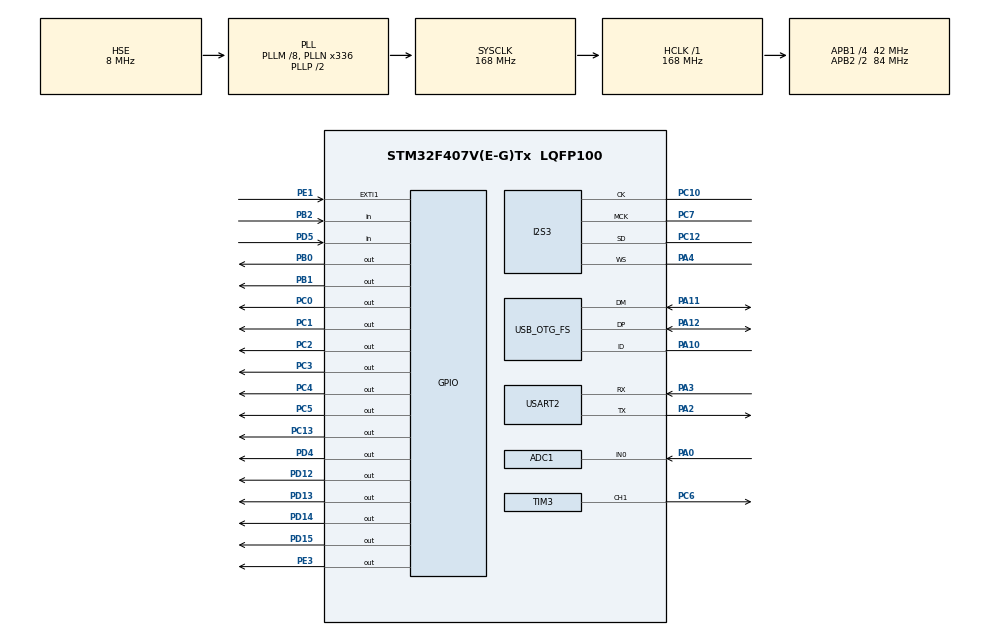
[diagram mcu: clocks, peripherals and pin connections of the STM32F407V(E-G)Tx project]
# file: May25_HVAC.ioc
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ADC1.Channel-0\#ChannelRegularConversion=ADC_CHANNEL_0
ADC1.NbrOfConversionFlag=1
ADC1.Rank-0\#ChannelRegularConversion=1
ADC1.SamplingTime-0\#ChannelRegularConversion=ADC_SAMPLETIME_3CYCLES
ADC1.master=1
I2S3.AudioFreq=I2S_AUDIOFREQ_48K
I2S3.ErrorAudioFreq=-2.34 %
I2S3.FullDuplexMode=I2S_FULLDUPLEXMODE_DISABLE
I2S3.Instance=SPI$Index
I2S3.RealAudioFreq=46.875 KHz
I2S3.VirtualMode=I2S_MODE_MASTER
Mcu.Family=STM32F4
Mcu.Name=STM32F407V(E-G)Tx
Mcu.Package=LQFP100
NVIC.PriorityGroup=NVIC_PRIORITYGROUP_4
PA0-WKUP.Signal=ADCx_IN0
PA10.Mode=OTG/Dual_Role_Device
PA10.Signal=USB_OTG_FS_ID
PA11.Mode=OTG/Dual_Role_Device
PA11.Signal=USB_OTG_FS_DM
PA12.Mode=OTG/Dual_Role_Device
PA12.Signal=USB_OTG_FS_DP
PA13.Signal=SYS_JTMS-SWDIO
PA14.Signal=SYS_JTCK-SWCLK
PA2.Mode=Asynchronous
PA2.Signal=USART2_TX
PA3.Mode=Asynchronous
PA3.Signal=USART2_RX
PA4.Mode=Half_Duplex_Master
PA4.Signal=I2S3_WS
PA9.Signal=USB_OTG_FS_VBUS
PB0.Signal=GPIO_Output
PB1.Signal=GPIO_Output
PB10.Signal=I2S2_CK
PB2.Signal=GPIO_Input
PB3.Signal=SYS_JTDO-SWO
PC0.Signal=GPIO_Output
PC1.Signal=GPIO_Output
PC10.Mode=Half_Duplex_Master
PC10.Signal=I2S3_CK
PC12.Mode=Half_Duplex_Master
PC12.Signal=I2S3_SD
PC13-ANTI_TAMP.Signal=GPIO_Output
PC14-OSC32_IN.Mode=LSE-External-Oscillator
PC14-OSC32_IN.Signal=RCC_OSC32_IN
PC15-OSC32_OUT.Mode=LSE-External-Oscillator
PC15-OSC32_OUT.Signal=RCC_OSC32_OUT
PC2.Signal=GPIO_Output
PC3.Signal=GPIO_Output
PC4.Signal=GPIO_Output
PC5.Signal=GPIO_Output
PC6.Signal=S_TIM3_CH1
PC7.Mode=Master_Clock_Activated
PC7.Signal=I2S3_MCK
PD12.Signal=GPIO_Output
PD13.Signal=GPIO_Output
PD14.Signal=GPIO_Output
PD15.Signal=GPIO_Output
PD4.Signal=GPIO_Output
PD5.Signal=GPIO_Input
PE1.Signal=GPXTI1
PE3.Signal=GPIO_Output
PH0-OSC_IN.Mode=HSE-External-Oscillator
PH0-OSC_IN.Signal=RCC_OSC_IN
PH1-OSC_OUT.Mode=HSE-External-Oscillator
PH1-OSC_OUT.Signal=RCC_OSC_OUT
ProjectManager.HeapSize=0x200
ProjectManager.StackSize=0x400
ProjectManager.TargetToolchain=STM32CubeIDE
RCC.48MHZClocksFreq_Value=48000000
RCC.AHBFreq_Value=168000000
RCC.APB1CLKDivider=RCC_HCLK_DIV4
RCC.APB1Freq_Value=42000000
RCC.APB1TimFreq_Value=84000000
RCC.APB2CLKDivider=RCC_HCLK_DIV2
RCC.APB2Freq_Value=84000000
RCC.APB2TimFreq_Value=168000000
RCC.CortexFreq_Value=168000000
RCC.HCLKFreq_Value=168000000
RCC.HSE_VALUE=8000000
RCC.HSI_VALUE=16000000
RCC.PLLM=8
RCC.PLLN=336
RCC.PLLQ=7
RCC.SYSCLKFreq_VALUE=168000000
RCC.SYSCLKSource=RCC_SYSCLKSOURCE_PLLCLK
RCC.VCOOutputFreq_Value=336000000
SH.ADCx_IN0.0=ADC1_IN0,IN0
SH.S_TIM3_CH1.0=TIM3_CH1,PWM Generation1 CH1
TIM3.Channel-PWM\ Generation1\ CH1=TIM_CHANNEL_1
TIM3.Period=999
TIM3.Prescaler=83
TIM3.Pulse-PWM\ Generation1\ CH1=800
USART2.VirtualMode=VM_ASYNC
board=custom

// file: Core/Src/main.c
/* USER CODE BEGIN Header */
/**
  ******************************************************************************
  * @file           : main.c
  * @brief          : Main program body
  ******************************************************************************
  * @attention
  *
  * Copyright (c) 2026 STMicroelectronics.
  * All rights reserved.
  *
  * This software is licensed under terms that can be found in the LICENSE file
  * in the root directory of this software component.
  * If no LICENSE file comes with this software, it is provided AS-IS.
  *
  ******************************************************************************
  */
/* USER CODE END Header */
#include "main.h"

/* USER CODE BEGIN Includes */
#include "hvac_app.h"
/* USER CODE END Includes */

ADC_HandleTypeDef hadc1;

I2S_HandleTypeDef hi2s3;

TIM_HandleTypeDef htim3;

UART_HandleTypeDef huart2;

void SystemClock_Config(void);
static void MX_GPIO_Init(void);
static void MX_ADC1_Init(void);
static void MX_TIM3_Init(void);
static void MX_USART2_UART_Init(void);
static void MX_I2S3_Init(void);
static void MX_USB_OTG_FS_USB_Init(void);

int main(void)
{

  /* MCU Configuration--------------------------------------------------------*/

  /* Reset of all peripherals, Initializes the Flash interface and the Systick. */
  HAL_Init();

  /* Configure the system clock */
  SystemClock_Config();

  /* Initialize all configured peripherals */
  MX_GPIO_Init();
  MX_ADC1_Init();
  MX_TIM3_Init();
  MX_USART2_UART_Init();
  MX_I2S3_Init();
  MX_USB_OTG_FS_USB_Init();
  /* USER CODE BEGIN 2 */
  hvac_app_init();
  /* USER CODE END 2 */

  /* Infinite loop */
  while (1)
  {

    /* USER CODE BEGIN 3 */
    hvac_app_task();
  }
  /* USER CODE END 3 */
}

void SystemClock_Config(void)
{
  RCC_OscInitTypeDef RCC_OscInitStruct = {0};
  RCC_ClkInitTypeDef RCC_ClkInitStruct = {0};

  /** Configure the main internal regulator output voltage
  */
  __HAL_RCC_PWR_CLK_ENABLE();
  __HAL_PWR_VOLTAGESCALING_CONFIG(PWR_REGULATOR_VOLTAGE_SCALE1);

  /** Initializes the RCC Oscillators according to the specified parameters
  * in the RCC_OscInitTypeDef structure.
  */
  RCC_OscInitStruct.OscillatorType = RCC_OSCILLATORTYPE_HSE;
  RCC_OscInitStruct.HSEState = RCC_HSE_ON;
  RCC_OscInitStruct.PLL.PLLState = RCC_PLL_ON;
  RCC_OscInitStruct.PLL.PLLSource = RCC_PLLSOURCE_HSE;
  RCC_OscInitStruct.PLL.PLLM = 8;
  RCC_OscInitStruct.PLL.PLLN = 336;
  RCC_OscInitStruct.PLL.PLLP = RCC_PLLP_DIV2;
  RCC_OscInitStruct.PLL.PLLQ = 7;
  if (HAL_RCC_OscConfig(&RCC_OscInitStruct) != HAL_OK)
  {
    Error_Handler();
  }

  /** Initializes the CPU, AHB and APB buses clocks
  */
  RCC_ClkInitStruct.ClockType = RCC_CLOCKTYPE_HCLK|RCC_CLOCKTYPE_SYSCLK
                              |RCC_CLOCKTYPE_PCLK1|RCC_CLOCKTYPE_PCLK2;
  RCC_ClkInitStruct.SYSCLKSource = RCC_SYSCLKSOURCE_PLLCLK;
  RCC_ClkInitStruct.AHBCLKDivider = RCC_SYSCLK_DIV1;
  RCC_ClkInitStruct.APB1CLKDivider = RCC_HCLK_DIV4;
  RCC_ClkInitStruct.APB2CLKDivider = RCC_HCLK_DIV2;

  if (HAL_RCC_ClockConfig(&RCC_ClkInitStruct, FLASH_LATENCY_5) != HAL_OK)
  {
    Error_Handler();
  }
}

static void MX_ADC1_Init(void)
{

  ADC_ChannelConfTypeDef sConfig = {0};

  /** Configure the global features of the ADC (Clock, Resolution, Data Alignment and number of conversion)
  */
  hadc1.Instance = ADC1;
  hadc1.Init.ClockPrescaler = ADC_CLOCK_SYNC_PCLK_DIV4;
  hadc1.Init.Resolution = ADC_RESOLUTION_12B;
  hadc1.Init.ScanConvMode = DISABLE;
  hadc1.Init.ContinuousConvMode = DISABLE;
  hadc1.Init.DiscontinuousConvMode = DISABLE;
  hadc1.Init.ExternalTrigConvEdge = ADC_EXTERNALTRIGCONVEDGE_NONE;
  hadc1.Init.ExternalTrigConv = ADC_SOFTWARE_START;
  hadc1.Init.DataAlign = ADC_DATAALIGN_RIGHT;
  hadc1.Init.NbrOfConversion = 1;
  hadc1.Init.DMAContinuousRequests = DISABLE;
  hadc1.Init.EOCSelection = ADC_EOC_SINGLE_CONV;
  if (HAL_ADC_Init(&hadc1) != HAL_OK)
  {
    Error_Handler();
  }

  /** Configure for the selected ADC regular channel its corresponding rank in the sequencer and its sample time.
  */
  sConfig.Channel = ADC_CHANNEL_0;
  sConfig.Rank = 1;
  sConfig.SamplingTime = ADC_SAMPLETIME_3CYCLES;
  if (HAL_ADC_ConfigChannel(&hadc1, &sConfig) != HAL_OK)
  {
    Error_Handler();
  }

}

static void MX_I2S3_Init(void)
{

  hi2s3.Instance = SPI3;
  hi2s3.Init.Mode = I2S_MODE_MASTER_TX;
  hi2s3.Init.Standard = I2S_STANDARD_PHILIPS;
  hi2s3.Init.DataFormat = I2S_DATAFORMAT_16B;
  hi2s3.Init.MCLKOutput = I2S_MCLKOUTPUT_ENABLE;
  hi2s3.Init.AudioFreq = I2S_AUDIOFREQ_48K;
  hi2s3.Init.CPOL = I2S_CPOL_LOW;
  hi2s3.Init.ClockSource = I2S_CLOCK_PLL;
  hi2s3.Init.FullDuplexMode = I2S_FULLDUPLEXMODE_DISABLE;
  if (HAL_I2S_Init(&hi2s3) != HAL_OK)
  {
    Error_Handler();
  }

}

static void MX_TIM3_Init(void)
{

  TIM_MasterConfigTypeDef sMasterConfig = {0};
  TIM_OC_InitTypeDef sConfigOC = {0};

  htim3.Instance = TIM3;
  htim3.Init.Prescaler = 83;
  htim3.Init.CounterMode = TIM_COUNTERMODE_UP;
  htim3.Init.Period = 999;
  htim3.Init.ClockDivision = TIM_CLOCKDIVISION_DIV1;
  htim3.Init.AutoReloadPreload = TIM_AUTORELOAD_PRELOAD_DISABLE;
  if (HAL_TIM_PWM_Init(&htim3) != HAL_OK)
  {
    Error_Handler();
  }
  sMasterConfig.MasterOutputTrigger = TIM_TRGO_RESET;
  sMasterConfig.MasterSlaveMode = TIM_MASTERSLAVEMODE_DISABLE;
  if (HAL_TIMEx_MasterConfigSynchronization(&htim3, &sMasterConfig) != HAL_OK)
  {
    Error_Handler();
  }
  sConfigOC.OCMode = TIM_OCMODE_PWM1;
  sConfigOC.Pulse = 800;
  sConfigOC.OCPolarity = TIM_OCPOLARITY_HIGH;
  sConfigOC.OCFastMode = TIM_OCFAST_DISABLE;
  if (HAL_TIM_PWM_ConfigChannel(&htim3, &sConfigOC, TIM_CHANNEL_1) != HAL_OK)
  {
    Error_Handler();
  }
  HAL_TIM_MspPostInit(&htim3);

}

static void MX_USART2_UART_Init(void)
{

  huart2.Instance = USART2;
  huart2.Init.BaudRate = 115200;
  huart2.Init.WordLength = UART_WORDLENGTH_8B;
  huart2.Init.StopBits = UART_STOPBITS_1;
  huart2.Init.Parity = UART_PARITY_NONE;
  huart2.Init.Mode = UART_MODE_TX_RX;
  huart2.Init.HwFlowCtl = UART_HWCONTROL_NONE;
  huart2.Init.OverSampling = UART_OVERSAMPLING_16;
  if (HAL_UART_Init(&huart2) != HAL_OK)
  {
    Error_Handler();
  }

}

static void MX_USB_OTG_FS_USB_Init(void)
{

}

static void MX_GPIO_Init(void)
{
  GPIO_InitTypeDef GPIO_InitStruct = {0};

  /* GPIO Ports Clock Enable */
  __HAL_RCC_GPIOE_CLK_ENABLE();
  __HAL_RCC_GPIOC_CLK_ENABLE();
  __HAL_RCC_GPIOH_CLK_ENABLE();
  __HAL_RCC_GPIOA_CLK_ENABLE();
  __HAL_RCC_GPIOB_CLK_ENABLE();
  __HAL_RCC_GPIOD_CLK_ENABLE();

  /*Configure GPIO pin Output Level */
  HAL_GPIO_WritePin(GPIOE, GPIO_PIN_3, GPIO_PIN_RESET);

  /*Configure GPIO pin Output Level */
  HAL_GPIO_WritePin(GPIOC, GPIO_PIN_13|GPIO_PIN_0|GPIO_PIN_1|GPIO_PIN_2
                          |GPIO_PIN_3|GPIO_PIN_4|GPIO_PIN_5, GPIO_PIN_RESET);

  /*Configure GPIO pin Output Level */
  HAL_GPIO_WritePin(GPIOB, GPIO_PIN_0|GPIO_PIN_1, GPIO_PIN_RESET);

  /*Configure GPIO pin Output Level */
  HAL_GPIO_WritePin(GPIOD, GPIO_PIN_12|GPIO_PIN_13|GPIO_PIN_14|GPIO_PIN_15
                          |GPIO_PIN_4, GPIO_PIN_RESET);

  /*Configure GPIO pin : PE3 */
  GPIO_InitStruct.Pin = GPIO_PIN_3;
  GPIO_InitStruct.Mode = GPIO_MODE_OUTPUT_PP;
  GPIO_InitStruct.Pull = GPIO_NOPULL;
  GPIO_InitStruct.Speed = GPIO_SPEED_FREQ_LOW;
  HAL_GPIO_Init(GPIOE, &GPIO_InitStruct);

  /*Configure GPIO pins : PC13 PC0 PC1 PC2
                           PC3 PC4 PC5 */
  GPIO_InitStruct.Pin = GPIO_PIN_13|GPIO_PIN_0|GPIO_PIN_1|GPIO_PIN_2
                          |GPIO_PIN_3|GPIO_PIN_4|GPIO_PIN_5;
  GPIO_InitStruct.Mode = GPIO_MODE_OUTPUT_PP;
  GPIO_InitStruct.Pull = GPIO_NOPULL;
  GPIO_InitStruct.Speed = GPIO_SPEED_FREQ_LOW;
  HAL_GPIO_Init(GPIOC, &GPIO_InitStruct);

  /*Configure GPIO pins : PB0 PB1 */
  GPIO_InitStruct.Pin = GPIO_PIN_0|GPIO_PIN_1;
  GPIO_InitStruct.Mode = GPIO_MODE_OUTPUT_PP;
  GPIO_InitStruct.Pull = GPIO_NOPULL;
  GPIO_InitStruct.Speed = GPIO_SPEED_FREQ_LOW;
  HAL_GPIO_Init(GPIOB, &GPIO_InitStruct);

  /*Configure GPIO pin : PB2 */
  GPIO_InitStruct.Pin = GPIO_PIN_2;
  GPIO_InitStruct.Mode = GPIO_MODE_INPUT;
  GPIO_InitStruct.Pull = GPIO_NOPULL;
  HAL_GPIO_Init(GPIOB, &GPIO_InitStruct);

  /*Configure GPIO pin : PB10 */
  GPIO_InitStruct.Pin = GPIO_PIN_10;
  GPIO_InitStruct.Mode = GPIO_MODE_AF_PP;
  GPIO_InitStruct.Pull = GPIO_NOPULL;
  GPIO_InitStruct.Speed = GPIO_SPEED_FREQ_LOW;
  GPIO_InitStruct.Alternate = GPIO_AF5_SPI2;
  HAL_GPIO_Init(GPIOB, &GPIO_InitStruct);

  /*Configure GPIO pins : PD12 PD13 PD14 PD15
                           PD4 */
  GPIO_InitStruct.Pin = GPIO_PIN_12|GPIO_PIN_13|GPIO_PIN_14|GPIO_PIN_15
                          |GPIO_PIN_4;
  GPIO_InitStruct.Mode = GPIO_MODE_OUTPUT_PP;
  GPIO_InitStruct.Pull = GPIO_NOPULL;
  GPIO_InitStruct.Speed = GPIO_SPEED_FREQ_LOW;
  HAL_GPIO_Init(GPIOD, &GPIO_InitStruct);

  /*Configure GPIO pin : PA9 */
  GPIO_InitStruct.Pin = GPIO_PIN_9;
  GPIO_InitStruct.Mode = GPIO_MODE_INPUT;
  GPIO_InitStruct.Pull = GPIO_NOPULL;
  HAL_GPIO_Init(GPIOA, &GPIO_InitStruct);

  /*Configure GPIO pins : PA10 PA11 PA12 */
  GPIO_InitStruct.Pin = GPIO_PIN_10|GPIO_PIN_11|GPIO_PIN_12;
  GPIO_InitStruct.Mode = GPIO_MODE_AF_PP;
  GPIO_InitStruct.Pull = GPIO_NOPULL;
  GPIO_InitStruct.Speed = GPIO_SPEED_FREQ_VERY_HIGH;
  GPIO_InitStruct.Alternate = GPIO_AF10_OTG_FS;
  HAL_GPIO_Init(GPIOA, &GPIO_InitStruct);

  /*Configure GPIO pin : PD5 */
  GPIO_InitStruct.Pin = GPIO_PIN_5;
  GPIO_InitStruct.Mode = GPIO_MODE_INPUT;
  GPIO_InitStruct.Pull = GPIO_NOPULL;
  HAL_GPIO_Init(GPIOD, &GPIO_InitStruct);

  /*Configure GPIO pin : PE1 */
  GPIO_InitStruct.Pin = GPIO_PIN_1;
  GPIO_InitStruct.Mode = GPIO_MODE_IT_RISING;
  GPIO_InitStruct.Pull = GPIO_NOPULL;
  HAL_GPIO_Init(GPIOE, &GPIO_InitStruct);

}

void Error_Handler(void)
{
  __disable_irq();
  while (1)
  {
  }
}
